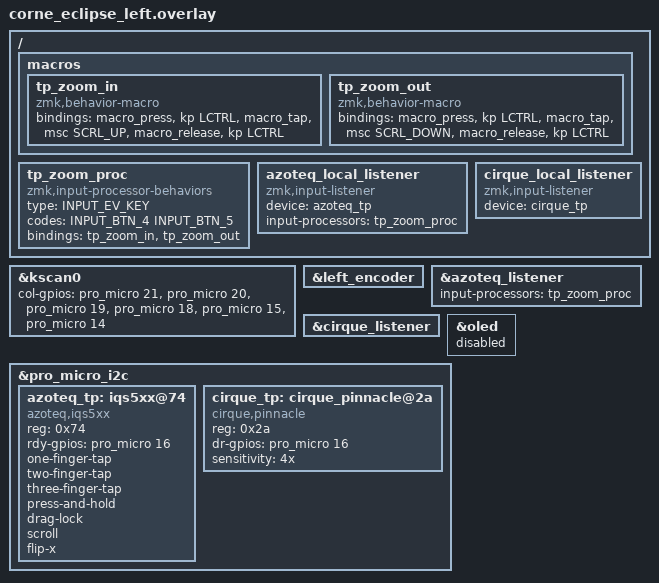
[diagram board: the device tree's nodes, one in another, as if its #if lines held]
/*
 * Copyright (c) 2020 Pete Johanson
 *
 * SPDX-License-Identifier: MIT
 */

#include "corne_eclipse.dtsi"

#if defined(TRACKPAD_PERIPHERAL) || defined(TRACKPAD_CENTRAL)
#include <dt-bindings/zmk/keys.h>
#include <dt-bindings/zmk/pointing.h>
#include <zephyr/dt-bindings/input/input-event-codes.h>

/* Map the trackpad's two-finger zoom to Ctrl+scroll (the de-facto zoom in
 * browsers/maps/image viewers). The forked Azoteq driver emits the zoom as KEY
 * clicks -- spread on INPUT_BTN_4, pinch on INPUT_BTN_5 -- because the behaviors
 * input processor is built for key events, not relative ones. Attached to
 * whichever listener consumes the trackpad on this (central) half below. */
/ {
    macros {
        tp_zoom_in: tp_zoom_in {
            compatible = "zmk,behavior-macro";
            #binding-cells = <0>;
            bindings = <&macro_press &kp LCTRL>
                     , <&macro_tap &msc SCRL_UP>
                     , <&macro_release &kp LCTRL>;
        };
        tp_zoom_out: tp_zoom_out {
            compatible = "zmk,behavior-macro";
            #binding-cells = <0>;
            bindings = <&macro_press &kp LCTRL>
                     , <&macro_tap &msc SCRL_DOWN>
                     , <&macro_release &kp LCTRL>;
        };
    };

    tp_zoom_proc: tp_zoom_proc {
        compatible = "zmk,input-processor-behaviors";
        #input-processor-cells = <0>;
        type = <INPUT_EV_KEY>;
        codes = <INPUT_BTN_4 INPUT_BTN_5>; /* zoom in (spread), zoom out (pinch) */
        bindings = <&tp_zoom_in &tp_zoom_out>;
    };
};
#endif

&kscan0 {
    col-gpios
        = <&pro_micro 21 GPIO_ACTIVE_HIGH>
        , <&pro_micro 20 GPIO_ACTIVE_HIGH>
        , <&pro_micro 19 GPIO_ACTIVE_HIGH>
        , <&pro_micro 18 GPIO_ACTIVE_HIGH>
        , <&pro_micro 15 GPIO_ACTIVE_HIGH>
        , <&pro_micro 14 GPIO_ACTIVE_HIGH>
        ;
};

&left_encoder {
    status = "okay";
};

#ifdef TRACKPAD_PERIPHERAL

/* The trackpad is on the peripheral (right) half; this central receives the
 * forwarded input and runs the listeners. The input-split proxy nodes and
 * their (disabled) listeners are defined in the shared .dtsi; enable them
 * here. The display stays on -- only the half with the physical trackpad
 * loses its display. */
&azoteq_listener {
    status = "okay";
    input-processors = <&tp_zoom_proc>;
};

&cirque_listener {
    status = "okay";
    /* If X/Y feel inverted after flashing, add e.g.:
     * input-processors = <&zip_xy_transform (INPUT_TRANSFORM_X_INVERT)>;
     */
};

#endif /* TRACKPAD_PERIPHERAL */

#ifdef TRACKPAD_CENTRAL

/* This (central) half physically hosts the trackpad. Display disabled for
 * the same I2C/SPI pin conflict as the peripheral case. A central-local
 * pointing device uses a DIRECT input-listener: it is already on the HID
 * host half, so no split forwarding is needed. The central also publishes
 * its status to the peripheral display (see corne_eclipse_left.conf). */
&oled {
    status = "disabled";
};

&pro_micro_i2c {
    azoteq_tp: iqs5xx@74 {
        compatible = "azoteq,iqs5xx";
        reg = <0x74>;
        rdy-gpios = <&pro_micro 16 GPIO_ACTIVE_HIGH>;
        one-finger-tap;
        two-finger-tap;
        three-finger-tap;
        press-and-hold;
        drag-lock;
        scroll;
        /* zoom; -- disabled: the 43mm pad is too small for the chip to detect a
         * pinch reliably, and at sensitive thresholds it steals scroll. */
        flip-x;
    };

    cirque_tp: cirque_pinnacle@2a {
        compatible = "cirque,pinnacle";
        reg = <0x2a>; /* 0x2c if the module's R1 jumper is bridged */
        dr-gpios = <&pro_micro 16 GPIO_ACTIVE_HIGH>;
        sensitivity = "4x";
    };
};

/ {
    azoteq_local_listener: azoteq_local_listener {
        compatible = "zmk,input-listener";
        device = <&azoteq_tp>;
        input-processors = <&tp_zoom_proc>;
    };

    cirque_local_listener: cirque_local_listener {
        compatible = "zmk,input-listener";
        device = <&cirque_tp>;
    };
};

#endif /* TRACKPAD_CENTRAL */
